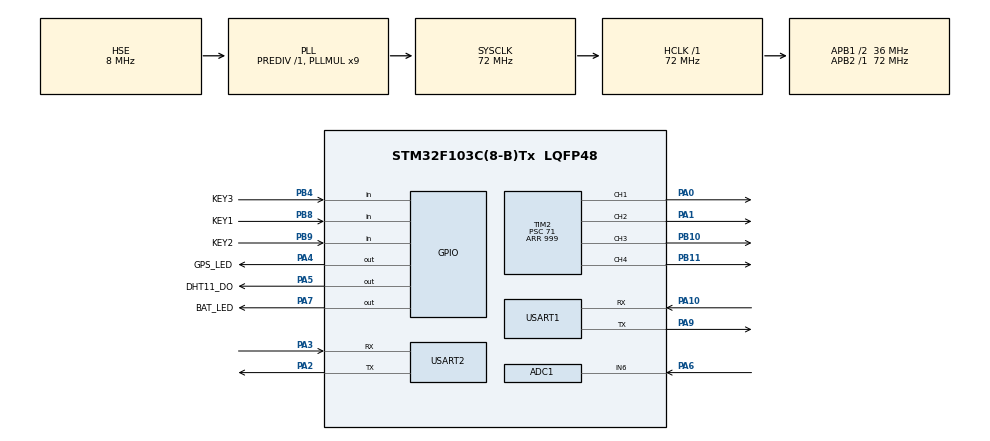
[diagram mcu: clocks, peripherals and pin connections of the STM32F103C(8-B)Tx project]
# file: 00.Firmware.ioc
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ADC1.Channel-2\#ChannelRegularConversion=ADC_CHANNEL_6
ADC1.NbrOfConversionFlag=1
ADC1.Rank-2\#ChannelRegularConversion=1
ADC1.SamplingTime-2\#ChannelRegularConversion=ADC_SAMPLETIME_1CYCLE_5
ADC1.master=1
Dma.Request0=USART1_RX
Dma.Request1=USART1_TX
Dma.USART1_RX.0.Direction=DMA_PERIPH_TO_MEMORY
Dma.USART1_RX.0.Instance=DMA1_Channel5
Dma.USART1_RX.0.MemDataAlignment=DMA_MDATAALIGN_BYTE
Dma.USART1_RX.0.MemInc=DMA_MINC_ENABLE
Dma.USART1_RX.0.Mode=DMA_NORMAL
Dma.USART1_RX.0.PeriphDataAlignment=DMA_PDATAALIGN_BYTE
Dma.USART1_RX.0.PeriphInc=DMA_PINC_DISABLE
Dma.USART1_RX.0.Priority=DMA_PRIORITY_LOW
Dma.USART1_TX.1.Direction=DMA_MEMORY_TO_PERIPH
Dma.USART1_TX.1.Instance=DMA1_Channel4
Dma.USART1_TX.1.MemDataAlignment=DMA_MDATAALIGN_BYTE
Dma.USART1_TX.1.MemInc=DMA_MINC_ENABLE
Dma.USART1_TX.1.Mode=DMA_NORMAL
Dma.USART1_TX.1.PeriphDataAlignment=DMA_PDATAALIGN_BYTE
Dma.USART1_TX.1.PeriphInc=DMA_PINC_DISABLE
Dma.USART1_TX.1.Priority=DMA_PRIORITY_LOW
Mcu.Family=STM32F1
Mcu.Name=STM32F103C(8-B)Tx
Mcu.Package=LQFP48
NVIC.DMA1_Channel4_IRQn=true\:0\:0\:false\:false\:true\:false\:true\:true
NVIC.DMA1_Channel5_IRQn=true\:0\:0\:false\:false\:true\:false\:true\:true
NVIC.PriorityGroup=NVIC_PRIORITYGROUP_4
NVIC.TIM1_UP_IRQn=true\:0\:0\:false\:false\:true\:true\:true\:true
NVIC.USART1_IRQn=true\:0\:0\:false\:false\:true\:true\:true\:true
NVIC.USART2_IRQn=true\:0\:0\:false\:false\:true\:true\:true\:true
PA0-WKUP.Signal=S_TIM2_CH1_ETR
PA1.Signal=S_TIM2_CH2
PA10.Mode=Asynchronous
PA10.Signal=USART1_RX
PA13.Mode=Serial_Wire
PA13.Signal=SYS_JTMS-SWDIO
PA14.Mode=Serial_Wire
PA14.Signal=SYS_JTCK-SWCLK
PA2.Mode=Asynchronous
PA2.Signal=USART2_TX
PA3.Mode=Asynchronous
PA3.Signal=USART2_RX
PA4.GPIO_Label=GPS_LED
PA4.Signal=GPIO_Output
PA5.GPIO_Label=DHT11_DO
PA5.Signal=GPIO_Output
PA6.Signal=ADCx_IN6
PA7.GPIO_Label=BAT_LED
PA7.Signal=GPIO_Output
PA9.Mode=Asynchronous
PA9.Signal=USART1_TX
PB10.Signal=S_TIM2_CH3
PB11.Signal=S_TIM2_CH4
PB4.GPIO_Label=KEY3
PB4.GPIO_PuPd=GPIO_PULLUP
PB4.Signal=GPIO_Input
PB8.GPIO_Label=KEY1
PB8.GPIO_PuPd=GPIO_PULLUP
PB8.Signal=GPIO_Input
PB9.GPIO_Label=KEY2
PB9.GPIO_PuPd=GPIO_PULLUP
PB9.Signal=GPIO_Input
PC14-OSC32_IN.Mode=LSE-External-Oscillator
PC14-OSC32_IN.Signal=RCC_OSC32_IN
PC15-OSC32_OUT.Mode=LSE-External-Oscillator
PC15-OSC32_OUT.Signal=RCC_OSC32_OUT
PD0-OSC_IN.Mode=HSE-External-Oscillator
PD0-OSC_IN.Signal=RCC_OSC_IN
PD1-OSC_OUT.Mode=HSE-External-Oscillator
PD1-OSC_OUT.Signal=RCC_OSC_OUT
ProjectManager.HeapSize=0x200
ProjectManager.StackSize=0x400
ProjectManager.TargetToolchain=MDK-ARM V5.32
RCC.ADCPresc=RCC_ADCPCLK2_DIV6
RCC.AHBFreq_Value=72000000
RCC.APB1CLKDivider=RCC_HCLK_DIV2
RCC.APB1Freq_Value=36000000
RCC.APB1TimFreq_Value=72000000
RCC.APB2Freq_Value=72000000
RCC.APB2TimFreq_Value=72000000
RCC.HCLKFreq_Value=72000000
RCC.PLLMUL=RCC_PLL_MUL9
RCC.PLLSourceVirtual=RCC_PLLSOURCE_HSE
RCC.SYSCLKFreq_VALUE=72000000
RCC.SYSCLKSource=RCC_SYSCLKSOURCE_PLLCLK
RCC.USBFreq_Value=72000000
SH.ADCx_IN6.0=ADC1_IN6,IN6
SH.S_TIM2_CH1_ETR.0=TIM2_CH1,PWM Generation1 CH1
SH.S_TIM2_CH2.0=TIM2_CH2,PWM Generation2 CH2
SH.S_TIM2_CH3.0=TIM2_CH3,PWM Generation3 CH3
SH.S_TIM2_CH4.0=TIM2_CH4,PWM Generation4 CH4
TIM1.Period=999
TIM1.Prescaler=71
TIM2.Channel-PWM\ Generation1\ CH1=TIM_CHANNEL_1
TIM2.Channel-PWM\ Generation2\ CH2=TIM_CHANNEL_2
TIM2.Channel-PWM\ Generation3\ CH3=TIM_CHANNEL_3
TIM2.Channel-PWM\ Generation4\ CH4=TIM_CHANNEL_4
TIM2.Period=999
TIM2.Prescaler=71
USART1.VirtualMode=VM_ASYNC
USART2.VirtualMode=VM_ASYNC
VP_TIM1_VS_ClockSourceINT.Mode=Internal
VP_TIM2_VS_ClockSourceINT.Mode=Internal
board=custom

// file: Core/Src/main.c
/* USER CODE BEGIN Header */
/**
  ******************************************************************************
  * @file           : main.c
  * @brief          : Main program body
  ******************************************************************************
  * @attention
  *
  * Copyright (c) 2025 STMicroelectronics.
  * All rights reserved.
  *
  * This software is licensed under terms that can be found in the LICENSE file
  * in the root directory of this software component.
  * If no LICENSE file comes with this software, it is provided AS-IS.
  *
  ******************************************************************************
  */
/* USER CODE END Header */
#include "main.h"
#include "adc.h"
#include "dma.h"
#include "tim.h"
#include "usart.h"
#include "gpio.h"

/* USER CODE BEGIN Includes */

#include "../USER/User.h"
/* USER CODE END Includes */

void SystemClock_Config(void);

int main(void)
{

  /* MCU Configuration--------------------------------------------------------*/

  /* Reset of all peripherals, Initializes the Flash interface and the Systick. */
  HAL_Init();

  /* Configure the system clock */
  SystemClock_Config();

  /* Initialize all configured peripherals */
  MX_GPIO_Init();
  MX_DMA_Init();
  MX_TIM1_Init();
  MX_TIM2_Init();
  MX_USART1_UART_Init();
  MX_USART2_UART_Init();
  MX_ADC1_Init();
  /* USER CODE BEGIN 2 */
  User_Init();
  printf("Hello World!\n");
  /* USER CODE END 2 */

  /* Infinite loop */
  while (1)
  {

    /* USER CODE BEGIN 3 */
  //   if (DHT11_Read(DHT11_DO_GPIO_Port,DHT11_DO_Pin,&dht11_data))
  //   {
  //     // 数据处理
  //     uint8_t humidity = dht11_data.humidity;
  //     uint8_t temperature = dht11_data.temperature;
  //     // 显示或发送数据
  //     printf("Humidity: %d %%\n",humidity);
  //     printf("Temperature: %d C\n",temperature);
  //  }
  //  Motor_Set_DieSpeed(&hMotor,MOTOR_DIR_FORWARD,5);
   User_Loop();
  }
  /* USER CODE END 3 */
}

void SystemClock_Config(void)
{
  RCC_OscInitTypeDef RCC_OscInitStruct = {0};
  RCC_ClkInitTypeDef RCC_ClkInitStruct = {0};
  RCC_PeriphCLKInitTypeDef PeriphClkInit = {0};

  /** Initializes the RCC Oscillators according to the specified parameters
  * in the RCC_OscInitTypeDef structure.
  */
  RCC_OscInitStruct.OscillatorType = RCC_OSCILLATORTYPE_HSE;
  RCC_OscInitStruct.HSEState = RCC_HSE_ON;
  RCC_OscInitStruct.HSEPredivValue = RCC_HSE_PREDIV_DIV1;
  RCC_OscInitStruct.HSIState = RCC_HSI_ON;
  RCC_OscInitStruct.PLL.PLLState = RCC_PLL_ON;
  RCC_OscInitStruct.PLL.PLLSource = RCC_PLLSOURCE_HSE;
  RCC_OscInitStruct.PLL.PLLMUL = RCC_PLL_MUL9;
  if (HAL_RCC_OscConfig(&RCC_OscInitStruct) != HAL_OK)
  {
    Error_Handler();
  }

  /** Initializes the CPU, AHB and APB buses clocks
  */
  RCC_ClkInitStruct.ClockType = RCC_CLOCKTYPE_HCLK|RCC_CLOCKTYPE_SYSCLK
                              |RCC_CLOCKTYPE_PCLK1|RCC_CLOCKTYPE_PCLK2;
  RCC_ClkInitStruct.SYSCLKSource = RCC_SYSCLKSOURCE_PLLCLK;
  RCC_ClkInitStruct.AHBCLKDivider = RCC_SYSCLK_DIV1;
  RCC_ClkInitStruct.APB1CLKDivider = RCC_HCLK_DIV2;
  RCC_ClkInitStruct.APB2CLKDivider = RCC_HCLK_DIV1;

  if (HAL_RCC_ClockConfig(&RCC_ClkInitStruct, FLASH_LATENCY_2) != HAL_OK)
  {
    Error_Handler();
  }
  PeriphClkInit.PeriphClockSelection = RCC_PERIPHCLK_ADC;
  PeriphClkInit.AdcClockSelection = RCC_ADCPCLK2_DIV6;
  if (HAL_RCCEx_PeriphCLKConfig(&PeriphClkInit) != HAL_OK)
  {
    Error_Handler();
  }
}

void Error_Handler(void)
{
  __disable_irq();
  while (1)
  {
  }
}
